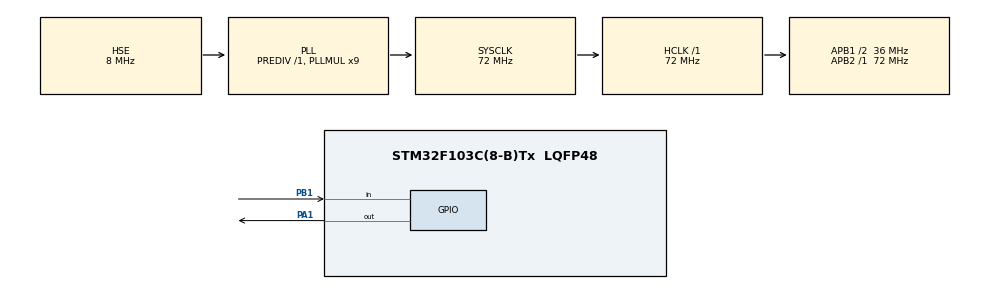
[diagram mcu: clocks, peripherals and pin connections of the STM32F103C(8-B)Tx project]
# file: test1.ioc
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Mcu.Family=STM32F1
Mcu.Name=STM32F103C(8-B)Tx
Mcu.Package=LQFP48
NVIC.PriorityGroup=NVIC_PRIORITYGROUP_4
PA1.Signal=GPIO_Output
PA13.Mode=Serial_Wire
PA13.Signal=SYS_JTMS-SWDIO
PA14.Mode=Serial_Wire
PA14.Signal=SYS_JTCK-SWCLK
PB1.Signal=GPIO_Input
PD0-OSC_IN.Mode=HSE-External-Oscillator
PD0-OSC_IN.Signal=RCC_OSC_IN
PD1-OSC_OUT.Mode=HSE-External-Oscillator
PD1-OSC_OUT.Signal=RCC_OSC_OUT
ProjectManager.HeapSize=0x200
ProjectManager.StackSize=0x400
ProjectManager.TargetToolchain=STM32CubeIDE
RCC.AHBFreq_Value=72000000
RCC.APB1CLKDivider=RCC_HCLK_DIV2
RCC.APB1Freq_Value=36000000
RCC.APB1TimFreq_Value=72000000
RCC.APB2Freq_Value=72000000
RCC.APB2TimFreq_Value=72000000
RCC.HCLKFreq_Value=72000000
RCC.PLLMUL=RCC_PLL_MUL9
RCC.PLLSourceVirtual=RCC_PLLSOURCE_HSE
RCC.SYSCLKFreq_VALUE=72000000
RCC.SYSCLKSource=RCC_SYSCLKSOURCE_PLLCLK
RCC.USBFreq_Value=72000000
TIM2.Period=1
TIM2.Prescaler=72-1
VP_TIM2_VS_ClockSourceINT.Mode=Internal
board=custom

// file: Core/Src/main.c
/* USER CODE BEGIN Header */
/**
  ******************************************************************************
  * @file           : main.c
  * @brief          : Main program body
  ******************************************************************************
  * @attention
  *
  * Copyright (c) 2022 STMicroelectronics.
  * All rights reserved.
  *
  * This software is licensed under terms that can be found in the LICENSE file
  * in the root directory of this software component.
  * If no LICENSE file comes with this software, it is provided AS-IS.
  *
  ******************************************************************************
  */
/* USER CODE END Header */
#include "main.h"

 TIM_HandleTypeDef htim2;

void SystemClock_Config(void);
static void MX_GPIO_Init(void);
static void MX_TIM2_Init(void);

int main(void)
{
  /* USER CODE BEGIN 1 */
	uint32_t timer_val; //starting timer value
	unsigned long count; //tracks the returned binary data from the HX711
	int i; //for loop index
  /* USER CODE END 1 */

  /* MCU Configuration--------------------------------------------------------*/

  /* Reset of all peripherals, Initializes the Flash interface and the Systick. */
  HAL_Init();

  /* Configure the system clock */
  SystemClock_Config();

  /* Initialize all configured peripherals */
  MX_GPIO_Init();
  MX_TIM2_Init();
  /* USER CODE BEGIN 2 */
  HAL_TIM_Base_Start_IT(&htim2); //start timer 2

  HAL_GPIO_WritePin(GPIOA,GPIO_PIN_1,0); //PD_SCK reset
  /* USER CODE END 2 */

  /* Infinite loop */
  /* USER CODE BEGIN WHILE */
  while (1)
  {
	  //reset timer here if necessary, not sure about the counter register size for timer
	  __HAL_TIM_SET_COUNTER(&htim2,0); //may need to check the syntax
	  count = 0; //reset stored binary data
    /* USER CODE END WHILE */

	  while(1){ //stops random signal fluctuation, checks for data transmission
		  if(HAL_GPIO_ReadPin(GPIOB, GPIO_PIN_1) == GPIO_PIN_RESET){
			  timer_val = __HAL_TIM_GET_COUNTER(&htim2); //assume this line of code executes fast
			  while((__HAL_TIM_GET_COUNTER(&htim2) - timer_val) < 1){//check for timer overflow problem

			  }
			  if(HAL_GPIO_ReadPin(GPIOB, GPIO_PIN_1) == GPIO_PIN_RESET){
				  break;
			  }
		  }
	  }

	 ///// while(HAL_GPIO_ReadPin(GPIOB, GPIO_PIN_1) != GPIO_PIN_RESET){ //assuming there is no delay for init of HX711
		  //traps the code execution
		  //wait for DOUT on the HX711 to become ready to send out data

		  /* may need to check for sudden spikes here */
	 ///// }

	  timer_val = __HAL_TIM_GET_COUNTER(&htim2); //assume this line of code executes fast
	  while((__HAL_TIM_GET_COUNTER(&htim2) - timer_val) < 1){//check for timer overflow problem
		  //makes sure that 1 us has passed to satisfy the T1 requirement
	  }

    /* USER CODE BEGIN 3 */
	  for(i=0;i<24;i++){
		  HAL_GPIO_WritePin(GPIOA,GPIO_PIN_1,GPIO_PIN_SET);
		  timer_val = __HAL_TIM_GET_COUNTER(&htim2); //assume this line of code executes fast
		  while((__HAL_TIM_GET_COUNTER(&htim2) - timer_val) < 1){//check for timer overflow problem
		  		  //makes sure that 1 us has passed to satisfy the T2 and T3 min. requirement
		  }

		  count=count<<1; //left shift to creat space to accept a new bit from the HX711

		  HAL_GPIO_WritePin(GPIOA,GPIO_PIN_1,GPIO_PIN_RESET); //satisfies the T3 max. requirement
		  /*make sure the time between setting and resetting the pulse to the HX711 does not exceed 50 us
		   * so we need to check above code */

		  if(HAL_GPIO_ReadPin(GPIOB,GPIO_PIN_1)==1){
			  count++;
			  //the time taken to read the value should also be enough to satisfy the T4 requirement
		  }
	  }

	  HAL_GPIO_WritePin(GPIOA,GPIO_PIN_1,GPIO_PIN_SET); //set up HX711 for gain of 128
	  timer_val = __HAL_TIM_GET_COUNTER(&htim2); //assume this line of code executes fast
	  while((__HAL_TIM_GET_COUNTER(&htim2) - timer_val) < 2){//check for timer overflow problem
	 		  		  //2 us delay, need to check if this way of us delay is valid
	  }

	  count=count^0x800000; //something that is always done in example code for some reason, need to figure out why
	  HAL_GPIO_WritePin(GPIOA,GPIO_PIN_1,GPIO_PIN_RESET);

	  /* may need to disable interrupt for the above code */
	  /* find a way to keep track of the values in the debug session */
  }
  /* USER CODE END 3 */
}

void SystemClock_Config(void)
{
  RCC_OscInitTypeDef RCC_OscInitStruct = {0};
  RCC_ClkInitTypeDef RCC_ClkInitStruct = {0};

  /** Initializes the RCC Oscillators according to the specified parameters
  * in the RCC_OscInitTypeDef structure.
  */
  RCC_OscInitStruct.OscillatorType = RCC_OSCILLATORTYPE_HSE;
  RCC_OscInitStruct.HSEState = RCC_HSE_ON;
  RCC_OscInitStruct.HSEPredivValue = RCC_HSE_PREDIV_DIV1;
  RCC_OscInitStruct.HSIState = RCC_HSI_ON;
  RCC_OscInitStruct.PLL.PLLState = RCC_PLL_ON;
  RCC_OscInitStruct.PLL.PLLSource = RCC_PLLSOURCE_HSE;
  RCC_OscInitStruct.PLL.PLLMUL = RCC_PLL_MUL9;
  if (HAL_RCC_OscConfig(&RCC_OscInitStruct) != HAL_OK)
  {
    Error_Handler();
  }

  /** Initializes the CPU, AHB and APB buses clocks
  */
  RCC_ClkInitStruct.ClockType = RCC_CLOCKTYPE_HCLK|RCC_CLOCKTYPE_SYSCLK
                              |RCC_CLOCKTYPE_PCLK1|RCC_CLOCKTYPE_PCLK2;
  RCC_ClkInitStruct.SYSCLKSource = RCC_SYSCLKSOURCE_PLLCLK;
  RCC_ClkInitStruct.AHBCLKDivider = RCC_SYSCLK_DIV1;
  RCC_ClkInitStruct.APB1CLKDivider = RCC_HCLK_DIV2;
  RCC_ClkInitStruct.APB2CLKDivider = RCC_HCLK_DIV1;

  if (HAL_RCC_ClockConfig(&RCC_ClkInitStruct, FLASH_LATENCY_2) != HAL_OK)
  {
    Error_Handler();
  }
}

static void MX_TIM2_Init(void)
{

  TIM_ClockConfigTypeDef sClockSourceConfig = {0};
  TIM_MasterConfigTypeDef sMasterConfig = {0};

  htim2.Instance = TIM2;
  htim2.Init.Prescaler = 72-1;
  htim2.Init.CounterMode = TIM_COUNTERMODE_UP;
  htim2.Init.Period = 1;
  htim2.Init.ClockDivision = TIM_CLOCKDIVISION_DIV1;
  htim2.Init.AutoReloadPreload = TIM_AUTORELOAD_PRELOAD_DISABLE;
  if (HAL_TIM_Base_Init(&htim2) != HAL_OK)
  {
    Error_Handler();
  }
  sClockSourceConfig.ClockSource = TIM_CLOCKSOURCE_INTERNAL;
  if (HAL_TIM_ConfigClockSource(&htim2, &sClockSourceConfig) != HAL_OK)
  {
    Error_Handler();
  }
  sMasterConfig.MasterOutputTrigger = TIM_TRGO_RESET;
  sMasterConfig.MasterSlaveMode = TIM_MASTERSLAVEMODE_DISABLE;
  if (HAL_TIMEx_MasterConfigSynchronization(&htim2, &sMasterConfig) != HAL_OK)
  {
    Error_Handler();
  }

}

static void MX_GPIO_Init(void)
{
  GPIO_InitTypeDef GPIO_InitStruct = {0};

  /* GPIO Ports Clock Enable */
  __HAL_RCC_GPIOD_CLK_ENABLE();
  __HAL_RCC_GPIOA_CLK_ENABLE();
  __HAL_RCC_GPIOB_CLK_ENABLE();

  /*Configure GPIO pin Output Level */
  HAL_GPIO_WritePin(GPIOA, GPIO_PIN_1, GPIO_PIN_RESET);

  /*Configure GPIO pin : PA1 */
  GPIO_InitStruct.Pin = GPIO_PIN_1;
  GPIO_InitStruct.Mode = GPIO_MODE_OUTPUT_PP;
  GPIO_InitStruct.Pull = GPIO_NOPULL;
  GPIO_InitStruct.Speed = GPIO_SPEED_FREQ_LOW;
  HAL_GPIO_Init(GPIOA, &GPIO_InitStruct);

  /*Configure GPIO pin : PB1 */
  GPIO_InitStruct.Pin = GPIO_PIN_1;
  GPIO_InitStruct.Mode = GPIO_MODE_INPUT;
  GPIO_InitStruct.Pull = GPIO_NOPULL;
  HAL_GPIO_Init(GPIOB, &GPIO_InitStruct);

}

void Error_Handler(void)
{
  __disable_irq();
  while (1)
  {
  }
}
